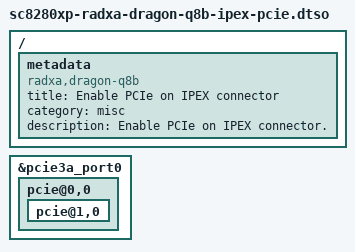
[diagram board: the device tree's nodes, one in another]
// SPDX-License-Identifier: BSD-3-Clause
/*
 * Copyright (c) 2026 Radxa Computer (Shenzhen) Co., Ltd.
 */

/dts-v1/;
/plugin/;

/ {
	metadata {
		title = "Enable PCIe on IPEX connector";
		compatible = "radxa,dragon-q8b";
		category = "misc";
		description = "Enable PCIe on IPEX connector.";
	};
};

&pcie3a_port0 {
	pcie@0,0 {
		pcie@1,0 {
			status = "okay";
		};
	};
};
